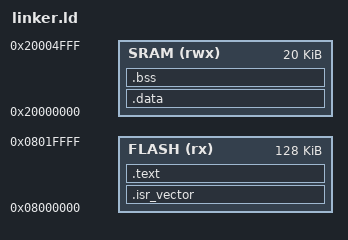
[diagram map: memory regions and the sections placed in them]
ENTRY(_reset_handler)

MEMORY
{
  FLASH (rx) : ORIGIN = 0x08000000, LENGTH = 128K
  SRAM  (rwx): ORIGIN = 0x20000000, LENGTH = 20K
}

/* initial stack symbol */
_estack = ORIGIN(SRAM) + LENGTH(SRAM);

SECTIONS
{
  .isr_vector :
  {
    KEEP(*(.isr_vector))
  } > FLASH

  .text :
  {
    *(.text*)
    *(.rodata*)
  } > FLASH

  .data : AT(ADDR(.text) + SIZEOF(.text))
  {
    _sdata = .;
    *(.data*)
    _edata = .;
  } > SRAM
    _sidata = LOADADDR(.data);
  .bss (NOLOAD) :
  {
    _sbss = .;
    *(.bss*)
    *(COMMON)
    _ebss = .;
  } > SRAM

  /* stack/top symbol for C code */
  _end = .;
}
